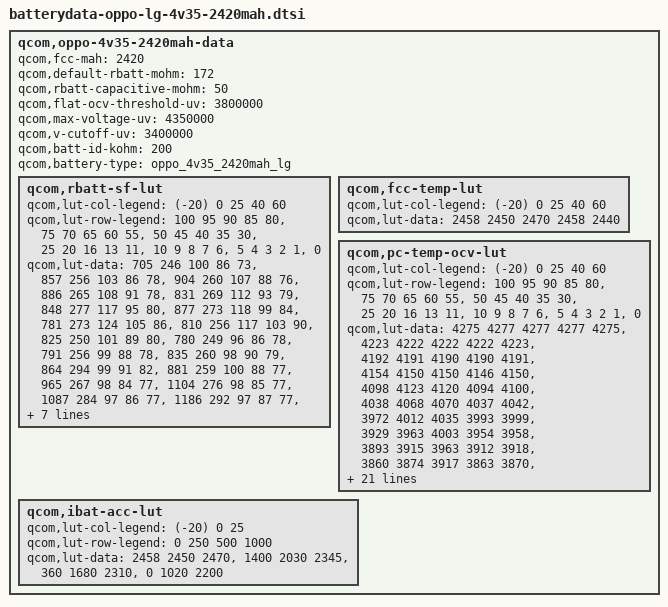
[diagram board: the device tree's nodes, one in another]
/* Copyright (c) 2013, The Linux Foundation. All rights reserved.
 *
 * This program is free software; you can redistribute it and/or modify
 * it under the terms of the GNU General Public License version 2 and
 * only version 2 as published by the Free Software Foundation.
 *
 * This program is distributed in the hope that it will be useful,
 * but WITHOUT ANY WARRANTY; without even the implied warranty of
 * MERCHANTABILITY or FITNESS FOR A PARTICULAR PURPOSE.  See the
 * GNU General Public License for more details.
 */

qcom,oppo-4v35-2420mah-data {
	qcom,fcc-mah = <2420>;
	qcom,default-rbatt-mohm = <172>;
	qcom,rbatt-capacitive-mohm = <50>;
	qcom,flat-ocv-threshold-uv = <3800000>;
	qcom,max-voltage-uv = <4350000>;
	qcom,v-cutoff-uv = <3400000>;
	qcom,batt-id-kohm = <200>;
	qcom,battery-type = "oppo_4v35_2420mah_lg";

	qcom,rbatt-sf-lut {
		qcom,lut-col-legend = <(-20) 0 25 40 60>;
		qcom,lut-row-legend = <100 95 90 85 80>,
				<75 70 65 60 55>,
				<50 45 40 35 30>,
				<25 20 16 13 11>,
				<10 9 8 7 6>,
				<5 4 3 2 1>,
				<0>;
		qcom,lut-data = <705 246 100 86 73>,
				<857 256 103 86 78>,
				<904 260 107 88 76>,
				<886 265 108 91 78>,
				<831 269 112 93 79>,
				<848 277 117 95 80>,
				<877 273 118 99 84>,
				<781 273 124 105 86>,
				<810 256 117 103 90>,
				<825 250 101 89 80>,
				<780 249 96 86 78>,
				<791 256 99 88 78>,
				<835 260 98 90 79>,
				<864 294 99 91 82>,
				<881 259 100 88 77>,
				<965 267 98 84 77>,
				<1104 276 98 85 77>,
				<1087 284 97 86 77>,
				<1186 292 97 87 77>,
				<1233 300 99 87 79>,
				<1304 314 100 89 80>,
				<1345 320 104 93 82>,
				<1385 339 108 94 82>,
				<1432 370 111 93 82>,
				<1551 389 115 97 82>,
				<1628 412 115 96 83>,
				<4049 455 118 99 87>,
				<7555 495 125 101 91>,
				<12164 548 129 116 105>,
				<24226 636 145 146 129>,
				<135251 124940 300 293 300>;
	};

	qcom,fcc-temp-lut {
		qcom,lut-col-legend = <(-20) 0 25 40 60>;
		qcom,lut-data = <2458 2450 2470 2458 2440>;
	};

	qcom,pc-temp-ocv-lut {
		qcom,lut-col-legend = <(-20) 0 25 40 60>;
		qcom,lut-row-legend = <100 95 90 85 80>,
				<75 70 65 60 55>,
				<50 45 40 35 30>,
				<25 20 16 13 11>,
				<10 9 8 7 6>,
				<5 4 3 2 1>,
				<0>;
		qcom,lut-data = <4275 4277 4277 4277 4275>,
				<4223 4222 4222 4222 4223>,
				<4192 4191 4190 4190 4191>,
				<4154 4150 4150 4146 4150>,
				<4098 4123 4120 4094 4100>,
				<4038 4068 4070 4037 4042>,
				<3972 4012 4035 3993 3999>,
				<3929 3963 4003 3954 3958>,
				<3893 3915 3963 3912 3918>,
				<3860 3874 3917 3863 3870>,
				<3833 3845 3866 3834 3841>,
				<3808 3824 3838 3808 3818>,
				<3788 3807 3817 3790 3799>,
				<3775 3791 3799 3776 3783>,
				<3766 3779 3784 3760 3762>,
				<3753 3770 3771 3742 3732>,
				<3736 3754 3757 3723 3712>,
				<3717 3728 3735 3699 3687>,
				<3704 3704 3710 3676 3669>,
				<3695 3699 3692 3670 3665>,
				<3688 3697 3684 3669 3664>,
				<3675 3693 3682 3666 3662>,
				<3666 3688 3679 3662 3660>,
				<3639 3682 3670 3647 3646>,
				<3617 3673 3654 3620 3624>,
				<3582 3612 3581 3582 3590>,
				<3534 3565 3529 3534 3549>,
				<3473 3504 3459 3473 3495>,
				<3392 3422 3364 3392 3329>,
				<3272 3297 3201 3272 3240>,
				<3000 3000 3000 3000 3000>;
	};

	qcom,ibat-acc-lut {
		qcom,lut-col-legend = <(-20) 0 25>;
		qcom,lut-row-legend = <0 250 500 1000>;
		qcom,lut-data = <2458 2450 2470>,
				<1400 2030 2345>,
				<360 1680 2310>,
				<0 1020 2200>;
	};
};
